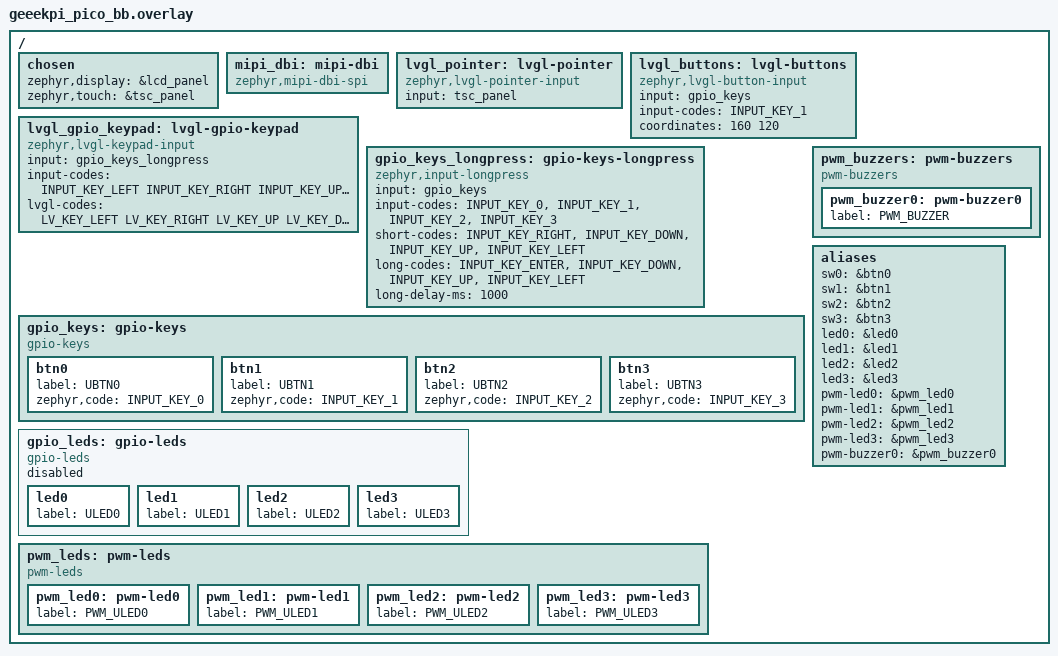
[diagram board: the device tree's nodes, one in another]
/*
 * SPDX-FileCopyrightText: Copyright (c) 2024-2026 TiaC Systems
 * SPDX-License-Identifier: Apache-2.0
 */

#include <zephyr/dt-bindings/input/input-event-codes.h>
#include <zephyr/dt-bindings/lvgl/lvgl.h>

/ {
	chosen {
		zephyr,display = &lcd_panel;
		zephyr,touch = &tsc_panel;
	};

	mipi_dbi: mipi-dbi {
		compatible = "zephyr,mipi-dbi-spi";
	};

	lvgl_pointer: lvgl-pointer {
		compatible = "zephyr,lvgl-pointer-input";
		input = <&tsc_panel>;
	};

	lvgl_buttons: lvgl-buttons {
		compatible = "zephyr,lvgl-button-input";
		input = <&gpio_keys>;
		input-codes = <INPUT_KEY_1>;
		coordinates = <160 120>;
	};

	lvgl_gpio_keypad: lvgl-gpio-keypad {
		compatible = "zephyr,lvgl-keypad-input";
		input = <&gpio_keys_longpress>;
		input-codes = <INPUT_KEY_LEFT INPUT_KEY_RIGHT
			       INPUT_KEY_UP INPUT_KEY_DOWN
			       INPUT_KEY_ENTER>;
		lvgl-codes = <LV_KEY_LEFT LV_KEY_RIGHT
			      LV_KEY_UP LV_KEY_DOWN
			      LV_KEY_ENTER>;
	};

	gpio_keys_longpress: gpio-keys-longpress {
		compatible = "zephyr,input-longpress";
		input = <&gpio_keys>;
		input-codes = <INPUT_KEY_0>, <INPUT_KEY_1>,
			      <INPUT_KEY_2>, <INPUT_KEY_3>;
		short-codes = <INPUT_KEY_RIGHT>, <INPUT_KEY_DOWN>,
			      <INPUT_KEY_UP>, <INPUT_KEY_LEFT>;
		long-codes = <INPUT_KEY_ENTER>, <INPUT_KEY_DOWN>,
			     <INPUT_KEY_UP>, <INPUT_KEY_LEFT>;
		long-delay-ms = <1000>;
	};

	/delete-node/ keys;
	/delete-node/ gpio_keys;
	/delete-node/ gpio-keys;
	gpio_keys: gpio-keys {
		compatible = "gpio-keys";
		status = "okay";

		btn0: btn0 {
			label = "UBTN0";
			zephyr,code = <INPUT_KEY_0>;
		};
		btn1: btn1 {
			label = "UBTN1";
			zephyr,code = <INPUT_KEY_1>;
		};
		btn2: btn2 {
			label = "UBTN2";
			zephyr,code = <INPUT_KEY_2>;
		};
		btn3: btn3 {
			label = "UBTN3";
			zephyr,code = <INPUT_KEY_3>;
		};
	};

	/delete-node/ leds;
	/delete-node/ gpio_leds;
	/delete-node/ gpio-leds;
	gpio_leds: gpio-leds {
		compatible = "gpio-leds";
		status = "disabled";

		led0: led0 {
			label = "ULED0";
		};
		led1: led1 {
			label = "ULED1";
		};
		led2: led2 {
			label = "ULED2";
		};
		led3: led3 {
			label = "ULED3";
		};
	};

	/delete-node/ pwm_leds;
	/delete-node/ pwm-leds;
	pwm_leds: pwm-leds {
		compatible = "pwm-leds";
		status = "okay";

		pwm_led0: pwm-led0 {
			label = "PWM_ULED0";
		};
		pwm_led1: pwm-led1 {
			label = "PWM_ULED1";
		};
		pwm_led2: pwm-led2 {
			label = "PWM_ULED2";
		};
		pwm_led3: pwm-led3 {
			label = "PWM_ULED3";
		};
	};

	/delete-node/ buzzers;
	/delete-node/ pwm_buzzers;
	/delete-node/ pwm-buzzers;
	pwm_buzzers: pwm-buzzers {
		compatible = "pwm-buzzers";
		status = "okay";

		pwm_buzzer0: pwm-buzzer0 {
			label = "PWM_BUZZER";
		};
	};

	aliases {
		/delete-property/ sw0;
		sw0 = &btn0;
		sw1 = &btn1;
		sw2 = &btn2;
		sw3 = &btn3;
		/delete-property/ led0;
		led0 = &led0;
		led1 = &led1;
		led2 = &led2;
		led3 = &led3;
		/delete-property/ pwm-led0;
		pwm-led0 = &pwm_led0;
		pwm-led1 = &pwm_led1;
		pwm-led2 = &pwm_led2;
		pwm-led3 = &pwm_led3;
		pwm-buzzer0 = &pwm_buzzer0;
	};
};
